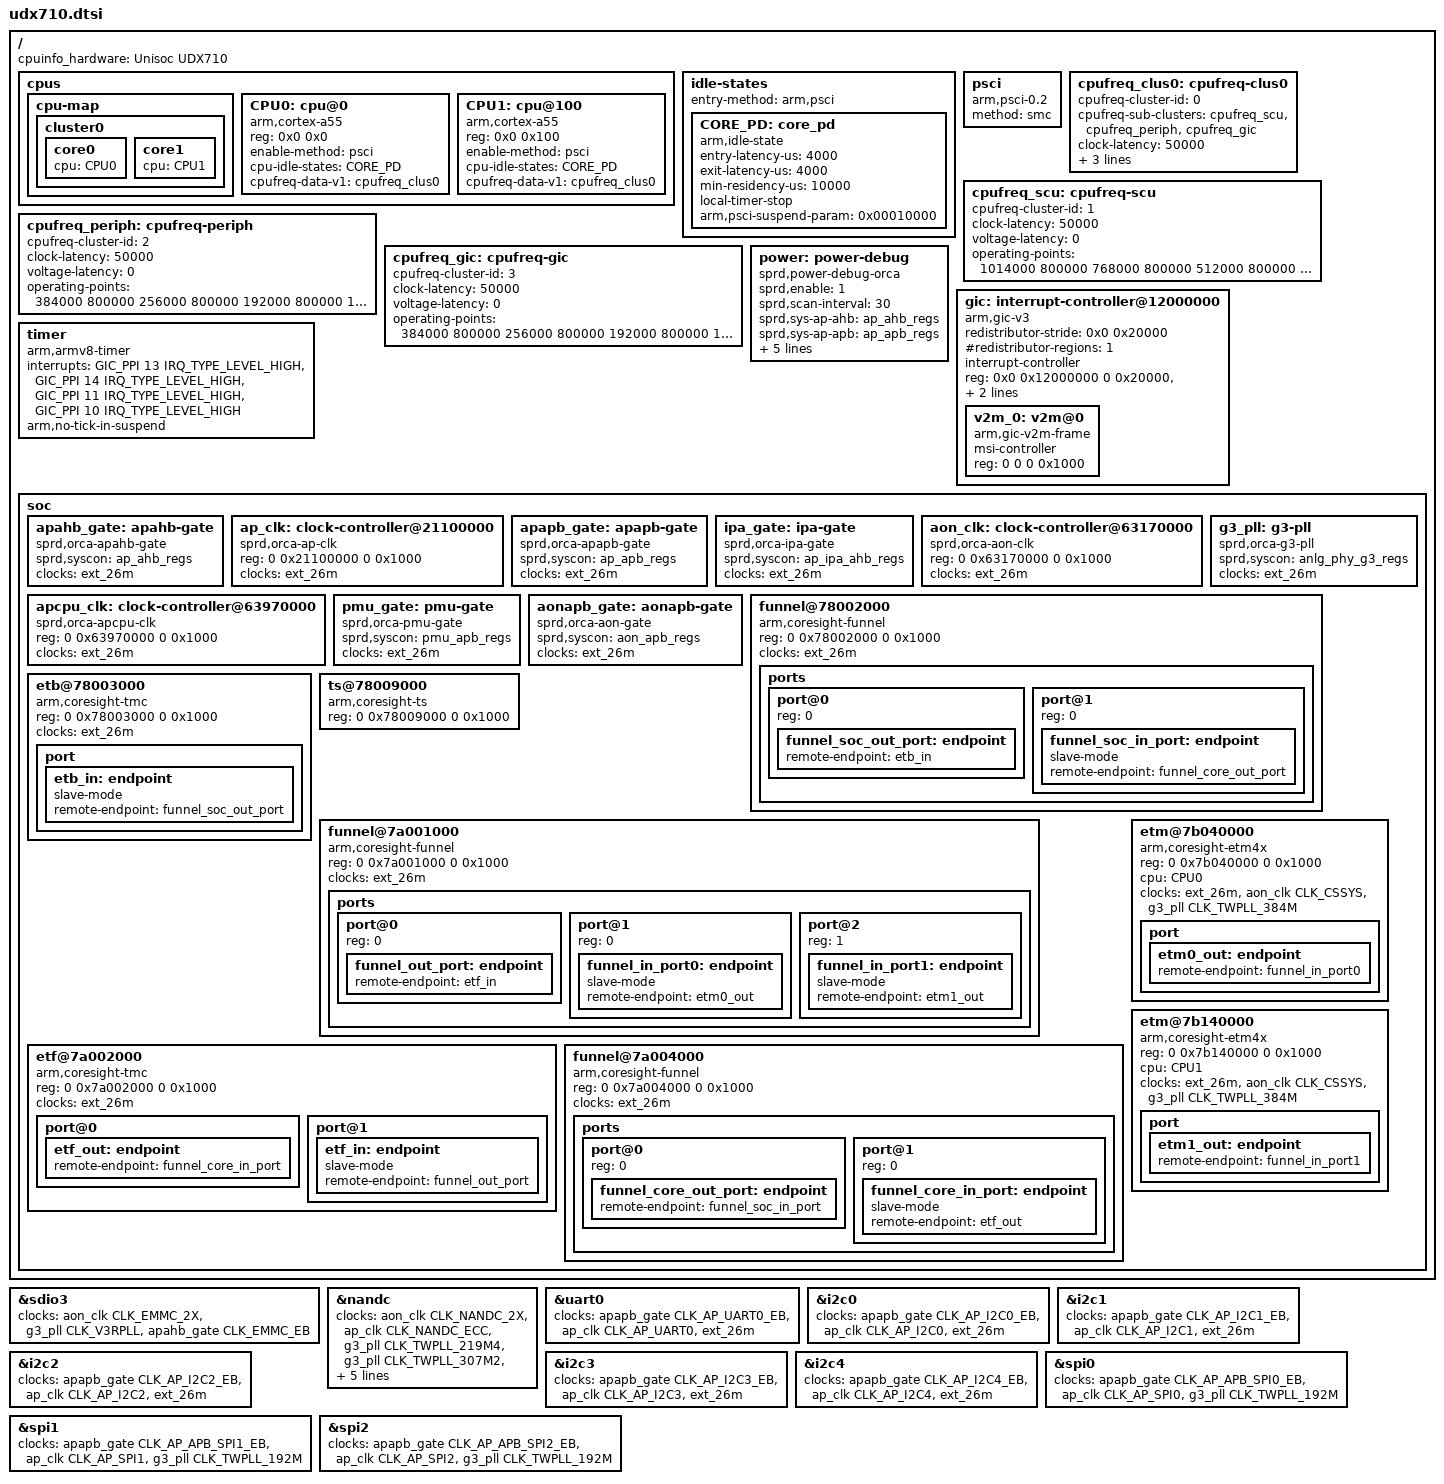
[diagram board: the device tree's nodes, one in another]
/*
 * Spreadtrum SC9650Haps SoC DTS file
 *
 * Copyright (C) 2017, Spreadtrum Communications Inc.
 *
 * This file is licensed under a dual GPLv2 or X11 license.
 */

#include "dt-bindings/clock/sprd,orca-clk.h"
#include "orca.dtsi"

/ {
	cpuinfo_hardware = "Unisoc UDX710";

	cpus {
		#address-cells = <2>;
		#size-cells = <0>;

		cpu-map {
			cluster0 {
				core0 {
					cpu = <&CPU0>;
				};
				core1 {
					cpu = <&CPU1>;
				};
			};
		};

		CPU0: cpu@0 {
			device_type = "cpu";
			compatible = "arm,cortex-a55","arm,armv8";
			reg = <0x0 0x0>;
			enable-method = "psci";
			cpu-idle-states = <&CORE_PD>;
			cpufreq-data-v1 = <&cpufreq_clus0>;
		};
		CPU1: cpu@100 {
			device_type = "cpu";
			compatible = "arm,cortex-a55","arm,armv8";
			reg = <0x0 0x100>;
			enable-method = "psci";
			cpu-idle-states = <&CORE_PD>;
			cpufreq-data-v1 = <&cpufreq_clus0>;
		};
	};

	idle-states {
		entry-method = "arm,psci";
		CORE_PD: core_pd {
			compatible = "arm,idle-state";
			entry-latency-us = <4000>;
			exit-latency-us = <4000>;
			min-residency-us = <10000>;
			local-timer-stop;
			arm,psci-suspend-param = <0x00010000>;
		};
	};

	psci {
		compatible = "arm,psci-0.2";
		method = "smc";
	};

	cpufreq_clus0: cpufreq-clus0 {
		cpufreq-cluster-id = <0>;
		cpufreq-sub-clusters =  <&cpufreq_scu>,
					<&cpufreq_periph>,
					<&cpufreq_gic>;
		clock-latency = <50000>;
		voltage-latency = <6413>;
		operating-points = <
			/*kHZ	uV*/
			1352000 800000
			1014000 800000
			768000  800000
			624000  800000
			512000  800000
			256000  800000
		>;
	};
	cpufreq_scu: cpufreq-scu {
		cpufreq-cluster-id = <1>;
		clock-latency = <50000>;
		voltage-latency = <0>;
		operating-points = <
			/*kHZ	uV*/
			1014000 800000
			768000  800000
			512000  800000
			468000  800000
			384000  800000
			192000  800000
		>;
	};

	cpufreq_periph: cpufreq-periph {
		cpufreq-cluster-id = <2>;
		clock-latency = <50000>;
		voltage-latency = <0>;
		operating-points = <
			/*kHZ	uV*/
			384000  800000
			256000  800000
			192000  800000
			153600  800000
			128000  800000
		>;
	};

	cpufreq_gic: cpufreq-gic {
		cpufreq-cluster-id = <3>;
		clock-latency = <50000>;
		voltage-latency = <0>;
		operating-points = <
			/*kHZ	uV*/
			384000  800000
			256000  800000
			192000  800000
			153600  800000
			128000  800000
		>;
	};

	power: power-debug {
		compatible = "sprd,power-debug-orca";
		#address-cells = <1>;
		#size-cells = <0>;

		sprd,enable = <1>;
		sprd,scan-interval = <30>;

		sprd,sys-ap-ahb = <&ap_ahb_regs>;
		sprd,sys-ap-apb = <&ap_apb_regs>;
		sprd,sys-pmu-apb = <&pmu_apb_regs>;
		sprd,sys-aon-apb = <&aon_apb_regs>;
		sprd,sys-ap-intc = <&ap_intc0_regs &ap_intc1_regs
				&ap_intc2_regs &ap_intc3_regs
				&ap_intc4_regs &ap_intc5_regs>;
	};

	gic: interrupt-controller@12000000 {
		compatible = "arm,gic-v3";
		#interrupt-cells = <3>;
		#address-cells = <2>;
		#size-cells = <2>;
		ranges;
		redistributor-stride = <0x0 0x20000>;	// 128KB stride
		#redistributor-regions = <1>;
		interrupt-controller;
		reg = <0x0 0x12000000 0 0x20000>,	// GICD
			<0x0 0x12040000 0 0x100000>;	// GICR
		interrupts = <1 9 4>;
		v2m_0: v2m@0 {
			compatible = "arm,gic-v2m-frame";
			msi-controller;
			reg = <0 0 0 0x1000>;
		};
	};

	timer {
		compatible = "arm,armv8-timer";
		interrupts = <GIC_PPI 13 IRQ_TYPE_LEVEL_HIGH>, /* Physical Secure PPI */
			<GIC_PPI 14 IRQ_TYPE_LEVEL_HIGH>, /* Physical Non-Secure PPI */
			<GIC_PPI 11 IRQ_TYPE_LEVEL_HIGH>, /* Virtual PPI */
			<GIC_PPI 10 IRQ_TYPE_LEVEL_HIGH>; /* Hipervisor PPI */
		arm,no-tick-in-suspend;
	};

	soc {
		apahb_gate: apahb-gate {
			compatible = "sprd,orca-apahb-gate";
			sprd,syscon = <&ap_ahb_regs>; /* 0x21000000 */
			clocks = <&ext_26m>;
			#clock-cells = <1>;
		};

		ap_clk: clock-controller@21100000 {
			compatible = "sprd,orca-ap-clk";
			reg = <0 0x21100000 0 0x1000>;
			clocks = <&ext_26m>;
			#clock-cells = <1>;
		};

		apapb_gate: apapb-gate {
			compatible = "sprd,orca-apapb-gate";
			sprd,syscon = <&ap_apb_regs>; /* 0x24000000 */
			clocks = <&ext_26m>;
			#clock-cells = <1>;
		};

		ipa_gate: ipa-gate {
			compatible = "sprd,orca-ipa-gate";
			sprd,syscon = <&ap_ipa_ahb_regs>;
			clocks = <&ext_26m>;
			#clock-cells = <1>;
		};

		aon_clk: clock-controller@63170000 {
			compatible = "sprd,orca-aon-clk";
			reg = <0 0x63170000 0 0x1000>;
			clocks = <&ext_26m>;
			#clock-cells = <1>;
		};

		g3_pll: g3-pll {
			compatible = "sprd,orca-g3-pll";
			sprd,syscon = <&anlg_phy_g3_regs>; /* 0x634b0000 */
			clocks = <&ext_26m>;
			#clock-cells = <1>;
		};

		apcpu_clk: clock-controller@63970000 {
			compatible = "sprd,orca-apcpu-clk";
			reg = <0 0x63970000 0 0x1000>;
			clocks = <&ext_26m>;
			#clock-cells = <1>;
		};

		pmu_gate: pmu-gate {
			compatible = "sprd,orca-pmu-gate";
			sprd,syscon = <&pmu_apb_regs>;	/* 0x64010000 */
			clocks = <&ext_26m>;
			#clock-cells = <1>;
		};

		aonapb_gate: aonapb-gate {
			compatible = "sprd,orca-aon-gate";
			sprd,syscon = <&aon_apb_regs>; /* 0x64020000 */
			clocks = <&ext_26m>;
			#clock-cells = <1>;
		};

		funnel@78002000 {
			compatible = "arm,coresight-funnel", "arm,primecell";
			reg = <0 0x78002000 0 0x1000>;
			clocks = <&ext_26m>;
			clock-names = "apb_pclk";
			ports {
				#address-cells = <1>;
				#size-cells = <0>;

				port@0 {
					reg = <0>;
					funnel_soc_out_port: endpoint {
						remote-endpoint = <&etb_in>;
					};
				};

				port@1 {
					reg = <0>;
					funnel_soc_in_port: endpoint {
						slave-mode;
						remote-endpoint = <&funnel_core_out_port>;
					};
				};
			};
		};

		etb@78003000 {
			compatible = "arm,coresight-tmc", "arm,primecell";
			reg = <0 0x78003000 0 0x1000>;
			clocks = <&ext_26m>;
			clock-names = "apb_pclk";
			port {
				etb_in: endpoint {
					slave-mode;
					remote-endpoint = <&funnel_soc_out_port>;
				};
			};
		};

		ts@78009000 {
			compatible = "arm,coresight-ts", "arm,primecell";
			reg = <0 0x78009000 0 0x1000>;
		};

		funnel@7a001000 {
			compatible = "arm,coresight-funnel", "arm,primecell";
			reg = <0 0x7a001000 0 0x1000>;
			clocks = <&ext_26m>;
			clock-names = "apb_pclk";

			ports {
				#address-cells = <1>;
				#size-cells = <0>;

				port@0 {
					reg = <0>;
					funnel_out_port: endpoint {
						remote-endpoint = <&etf_in>;
					};
				};

				port@1 {
					reg = <0>;
					funnel_in_port0: endpoint {
						slave-mode;
						remote-endpoint = <&etm0_out>;
					};
				};

				port@2 {
					reg = <1>;
					funnel_in_port1: endpoint {
						slave-mode;
						remote-endpoint = <&etm1_out>;
					};
				};
			};
		};

		etf@7a002000 {
			compatible = "arm,coresight-tmc", "arm,primecell";
			reg = <0 0x7a002000 0 0x1000>;
			clocks = <&ext_26m>;
			clock-names = "apb_pclk";

			port@0 {
				etf_out: endpoint {
					remote-endpoint = <&funnel_core_in_port>;
				};
			};

			port@1 {
				etf_in: endpoint {
					slave-mode;
					remote-endpoint = <&funnel_out_port>;
				};
			};
		};

		funnel@7a004000 {
			compatible = "arm,coresight-funnel", "arm,primecell";
			reg = <0 0x7a004000 0 0x1000>;
			clocks = <&ext_26m>;
			clock-names = "apb_pclk";
			ports {
				#address-cells = <1>;
				#size-cells = <0>;

				port@0 {
					reg = <0>;
					funnel_core_out_port: endpoint {
						remote-endpoint = <&funnel_soc_in_port>;
					};
				};

				port@1 {
					reg = <0>;
					funnel_core_in_port: endpoint {
						slave-mode;
						remote-endpoint = <&etf_out>;
					};
				};
			};
		};

		etm@7b040000 {
			compatible = "arm,coresight-etm4x", "arm,primecell";
			reg = <0 0x7b040000 0 0x1000>;
			cpu = <&CPU0>;
			clocks = <&ext_26m>, <&aon_clk CLK_CSSYS>, <&g3_pll CLK_TWPLL_384M>;
			clock-names = "apb_pclk", "clk_cs", "cs_src";

			port {
				etm0_out: endpoint {
					remote-endpoint = <&funnel_in_port0>;
				};
			};
		};

		etm@7b140000 {
			compatible = "arm,coresight-etm4x", "arm,primecell";
			reg = <0 0x7b140000 0 0x1000>;
			cpu = <&CPU1>;
			clocks = <&ext_26m>, <&aon_clk CLK_CSSYS>, <&g3_pll CLK_TWPLL_384M>;
			clock-names = "apb_pclk", "clk_cs", "cs_src";

			port {
				etm1_out: endpoint {
					remote-endpoint = <&funnel_in_port1>;
				};
			};
		};
	};
};

&sdio3 {
	clock-names = "sdio_clk","sdio_clk_source","sdio_ahb_enable";
	clocks = <&aon_clk CLK_EMMC_2X>,
		 <&g3_pll CLK_V3RPLL>,
		 <&apahb_gate CLK_EMMC_EB>;
};

&nandc {
	clock-names = "nandc_clk","nandc_ecc_clk","nandc_parent_sdr",
		"nandc_parent_ddr","nandc_ahb_enable","nandc_ecc_enable",
		"nandc_26m_enable","nandc_1x_enable","nandc_2x_enable";
	clocks = <&aon_clk CLK_NANDC_2X>,
		 <&ap_clk CLK_NANDC_ECC>,
		 <&g3_pll CLK_TWPLL_219M4>,
		 <&g3_pll CLK_TWPLL_307M2>,
		 <&apahb_gate CLK_NANDC_EB>,
		 <&apahb_gate CLK_NANDC_ECC_EB>,
		 <&apahb_gate CLK_NANDC_26M_EB>,
		 <&aonapb_gate CLK_NANDC_1X_EN>,
		 <&aonapb_gate CLK_NANDC_2X_EN>;
};

&uart0 {
	clock-names = "enable", "uart", "source";
	clocks = <&apapb_gate CLK_AP_UART0_EB>,
		 <&ap_clk CLK_AP_UART0>,
		 <&ext_26m>;
};

&i2c0 {
	clock-names ="enable", "i2c", "source";
	clocks = <&apapb_gate CLK_AP_I2C0_EB>,
		<&ap_clk CLK_AP_I2C0>, <&ext_26m>;
};

&i2c1 {
	clock-names ="enable", "i2c", "source";
	clocks = <&apapb_gate CLK_AP_I2C1_EB>,
		 <&ap_clk CLK_AP_I2C1>, <&ext_26m>;
};

&i2c2 {
	clock-names ="enable", "i2c", "source";
	clocks = <&apapb_gate CLK_AP_I2C2_EB>,
		 <&ap_clk CLK_AP_I2C2>, <&ext_26m>;
};

&i2c3 {
	clock-names ="enable", "i2c", "source";
	clocks = <&apapb_gate CLK_AP_I2C3_EB>,
		 <&ap_clk CLK_AP_I2C3>, <&ext_26m>;
};

&i2c4 {
	clock-names ="enable", "i2c", "source";
	clocks = <&apapb_gate CLK_AP_I2C4_EB>,
		 <&ap_clk CLK_AP_I2C4>, <&ext_26m>;
};

&spi0 {
	clock-names = "enable", "spi", "source";
	clocks = <&apapb_gate CLK_AP_APB_SPI0_EB>,
	<&ap_clk CLK_AP_SPI0>, <&g3_pll CLK_TWPLL_192M>;
};

&spi1 {
	clock-names = "enable", "spi", "source";
	clocks = <&apapb_gate CLK_AP_APB_SPI1_EB>,
	<&ap_clk CLK_AP_SPI1>, <&g3_pll CLK_TWPLL_192M>;
};

&spi2 {
	clock-names = "enable", "spi", "source";
	clocks = <&apapb_gate CLK_AP_APB_SPI2_EB>,
	<&ap_clk CLK_AP_SPI2>, <&g3_pll CLK_TWPLL_192M>;
};
